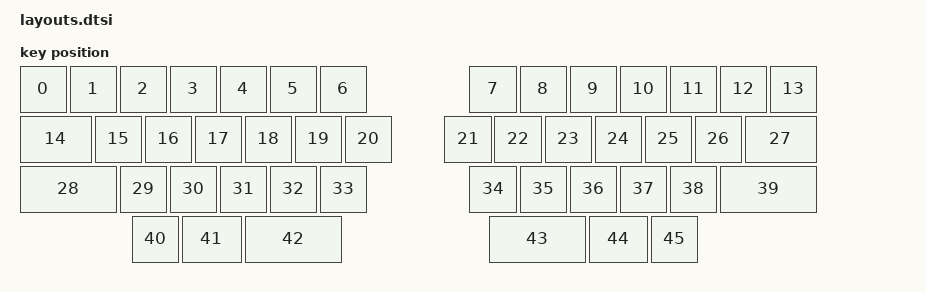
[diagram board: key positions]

#include <physical_layouts.dtsi>
/ {
    physical_layout0: physical_layout0 {
        compatible = "zmk,physical-layout";
        display-name = "Layout";
        keys
            = <&key_physical_attrs 100 100 (-50) 100 0 0 0>
			,<&key_physical_attrs 100 100 50 100 0 0 0>
			,<&key_physical_attrs 100 100 150 100 0 0 0>
			,<&key_physical_attrs 100 100 250 100 0 0 0>
			,<&key_physical_attrs 100 100 350 100 0 0 0>
			,<&key_physical_attrs 100 100 450 100 0 0 0>
			,<&key_physical_attrs 100 100 550 100 0 0 0>
			,<&key_physical_attrs 100 100 850 100 0 0 0>
			,<&key_physical_attrs 100 100 950 100 0 0 0>
			,<&key_physical_attrs 100 100 1050 100 0 0 0>
			,<&key_physical_attrs 100 100 1150 100 0 0 0>
			,<&key_physical_attrs 100 100 1250 100 0 0 0>
			,<&key_physical_attrs 100 100 1350 100 0 0 0>
			,<&key_physical_attrs 100 100 1450 100 0 0 0>
			,<&key_physical_attrs 150 100 (-50) 200 0 0 0>
			,<&key_physical_attrs 100 100 100 200 0 0 0>
			,<&key_physical_attrs 100 100 200 200 0 0 0>
			,<&key_physical_attrs 100 100 300 200 0 0 0>
			,<&key_physical_attrs 100 100 400 200 0 0 0>
			,<&key_physical_attrs 100 100 500 200 0 0 0>
			,<&key_physical_attrs 100 100 600 200 0 0 0>
			,<&key_physical_attrs 100 100 800 200 0 0 0>
			,<&key_physical_attrs 100 100 900 200 0 0 0>
			,<&key_physical_attrs 100 100 1000 200 0 0 0>
			,<&key_physical_attrs 100 100 1100 200 0 0 0>
			,<&key_physical_attrs 100 100 1200 200 0 0 0>
			,<&key_physical_attrs 100 100 1300 200 0 0 0>
			,<&key_physical_attrs 150 100 1400 200 0 0 0>
			,<&key_physical_attrs 200 100 (-50) 300 0 0 0>
			,<&key_physical_attrs 100 100 150 300 0 0 0>
			,<&key_physical_attrs 100 100 250 300 0 0 0>
			,<&key_physical_attrs 100 100 350 300 0 0 0>
			,<&key_physical_attrs 100 100 450 300 0 0 0>
			,<&key_physical_attrs 100 100 550 300 0 0 0>
			,<&key_physical_attrs 100 100 850 300 0 0 0>
			,<&key_physical_attrs 100 100 950 300 0 0 0>
			,<&key_physical_attrs 100 100 1050 300 0 0 0>
			,<&key_physical_attrs 100 100 1150 300 0 0 0>
			,<&key_physical_attrs 100 100 1250 300 0 0 0>
			,<&key_physical_attrs 200 100 1350 300 0 0 0>
			,<&key_physical_attrs 100 100 175 400 0 0 0>
			,<&key_physical_attrs 125 100 275 400 0 0 0>
			,<&key_physical_attrs 200 100 400 400 0 0 0>
			,<&key_physical_attrs 200 100 888 400 0 0 0>
			,<&key_physical_attrs 125 100 1088 400 0 0 0>
			,<&key_physical_attrs 100 100 1213 400 0 0 0>
            ;
    };
};
    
